VERSION ""
NS_ :

BS_:
BU_: DBG BLE GPS MOTOR SENSOR MASTER

BO_ 90 MASTER_HEARTBEAT: 1 MASTER
 SG_ MASTER_HEARTBEAT_cmd : 0|8@1+ (1,0) [0|0] "" MOTOR, SENSOR, GPS

BO_ 91 MOTOR_HEARTBEAT: 1 MOTOR
 SG_ MOTOR_HEARTBEAT_cmd : 0|8@1+ (1,0) [0|0] "" MASTER

BO_ 92 SENSOR_HEARTBEAT: 1 SENSOR
 SG_ SENSOR_HEARTBEAT_cmd : 0|8@1+ (1,0) [0|0] "" MASTER

BO_ 93 GPS_HEARTBEAT: 1 GPS
 SG_ GPS_HEARTBEAT_cmd : 0|8@1+ (1,0) [0|0] "" MASTER, BLE

BO_ 94 BLE_HEARTBEAT: 1 BLE
 SG_ BLE_HEARTBEAT_cmd : 0|8@1+ (1,0) [0|0] "" MASTER, GPS

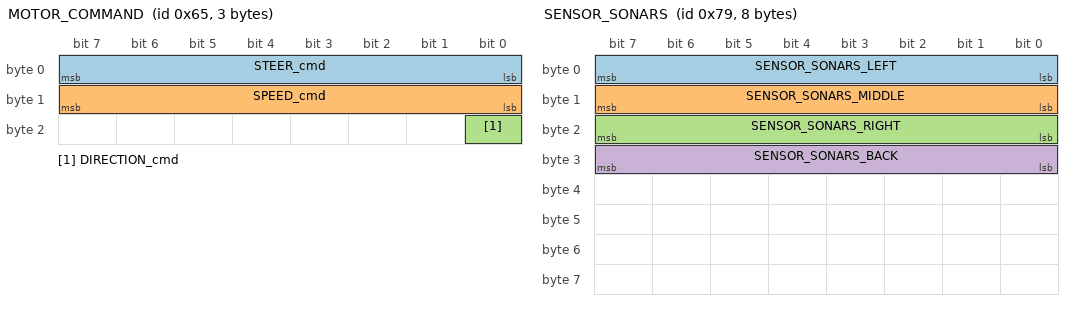
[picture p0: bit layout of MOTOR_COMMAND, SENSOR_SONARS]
BO_ 101 MOTOR_COMMAND: 3 MASTER
 SG_ STEER_cmd : 0|8@1- (1,0) [-2|2] "" MOTOR
 SG_ SPEED_cmd : 8|8@1- (0.1,0) [0|3.0] "m/s" MOTOR
 SG_ DIRECTION_cmd : 16|1@1+ (1,0) [0|0] "" MOTOR

BO_ 121 SENSOR_SONARS: 8 SENSOR
 SG_ SENSOR_SONARS_LEFT : 0|8@1+ (1,0) [0|0] "" MASTER
 SG_ SENSOR_SONARS_MIDDLE : 8|8@1+ (1,0) [0|0] "" MASTER
 SG_ SENSOR_SONARS_RIGHT : 16|8@1+ (1,0) [0|0] "" MASTER
 SG_ SENSOR_SONARS_BACK : 24|8@1+ (1,0) [0|0] "" MASTER

BO_ 141 DIRECTION_GPS: 2 GPS
 SG_ DIRECTION_VAL : 0|8@1- (1,0) [-2|2] "" MASTER
 SG_ DESTINATION_REACHED : 8|1@1+ (1,0) [0|0] "" MASTER

BO_ 161 SPEED_MOTOR: 2 MOTOR
 SG_ MOTOR_SPEED : 0|12@1+ (0.001,0) [0|0] "mph" MASTER

BO_ 181 APP_DATA: 8 BLE
 SG_ START_CAR : 0|2@1+ (1,0) [0|0] "" MASTER, DBG

BO_ 182 APP_DATA_LAT_LONG: 8 BLE
 SG_ DEST_LAT : 0|26@1+ (1,0) [0|0] "" MASTER,GPS
 SG_ DEST_LONG : 26|27@1+ (1,0) [0|0] "" MASTER,GPS

BO_ 191 HEADING: 4 GPS
 SG_ HEADING_VAL : 0|32@1+ (0.000001,0) [0|0] "" MOTOR, DBG

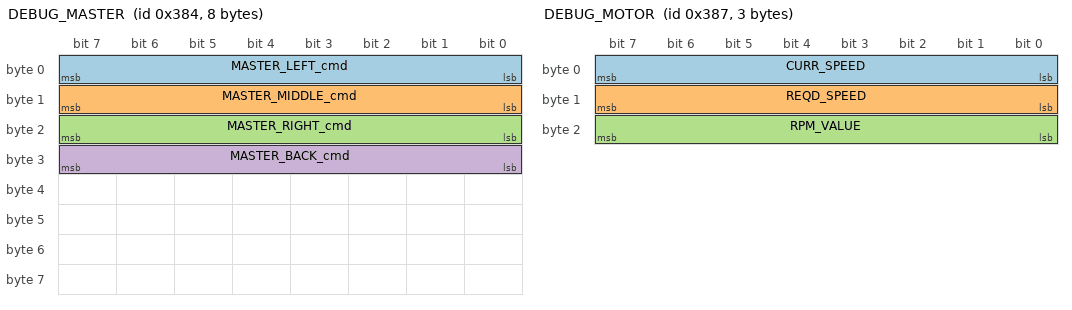
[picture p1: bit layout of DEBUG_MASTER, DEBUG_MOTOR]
BO_ 900 DEBUG_MASTER: 8 MASTER
 SG_ MASTER_LEFT_cmd : 0|8@1+ (1,0) [0|0] "" DBG
 SG_ MASTER_MIDDLE_cmd : 8|8@1+ (1,0) [0|0] "" DBG
 SG_ MASTER_RIGHT_cmd : 16|8@1+ (1,0) [0|0] "" DBG
 SG_ MASTER_BACK_cmd : 24|8@1+ (1,0) [0|0] "" DBG

BO_ 901 DEBUG_GPS: 8 GPS
 SG_ CURR_LAT : 0|32@1+ (0.000001,0) [36.000000|38.000000] "" DBG
 SG_ CURR_LONG : 32|32@1+ (0.000001,-123) [-123.000000|-120.000000] "" DBG

BO_ 902 DEBUG_COMPASS: 2 GPS
 SG_ HEADING : 0|16@1+ (1,0) [0|360] "degrees" DBG

BO_ 903 DEBUG_MOTOR: 3 MOTOR
 SG_ CURR_SPEED : 0|8@1+ (0.01,0) [0|0] "m/s" DBG
 SG_ REQD_SPEED : 8|8@1+ (0.01,0) [0|0] "m/s" DBG
 SG_ RPM_VALUE : 16|8@1+ (1,0) [0|0] "" DBG

BO_ 904 DEBUG_NAVIGATION: 8 GPS
 SG_ DIST_DIFF : 0|32@1+ (0.000001,0) [0|0] "m" DBG
 SG_ HEAD_DIFF : 32|32@1+ (0.000001,0) [0|0] "Degrees" DBG

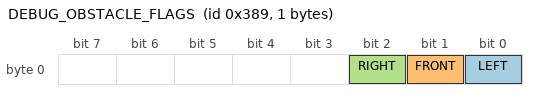
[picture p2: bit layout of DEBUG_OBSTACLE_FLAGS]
BO_ 905 DEBUG_OBSTACLE_FLAGS: 1 MASTER
 SG_ LEFT : 0|1@1+ (1,0) [0|0] "" DBG
 SG_ FRONT : 1|1@1+ (1,0) [0|0] "" DBG
 SG_ RIGHT : 2|1@1+ (1,0) [0|0] "" DBG

BO_ 899 DEBUG_BEARING: 4 GPS
 SG_ BEARING : 0|32@1+ (0.000001,0) [0|0] "degrees" DBG,MOTOR

BO_ 897 NXT_COORD: 8 GPS
 SG_ LAT : 0|32@1+ (0.000001,0) [36.000000|38.000000] "" DBG
 SG_ LONG : 32|32@1+ (0.000001,-123) [-123.000000|-120.000000] "" DBG

BO_ 896 CHECKPOINTS: 1 GPS
 SG_ COUNT : 0|8@1+ (1,0) [0|0] "" MOTOR

BO_ 898 DEBUG_CHECKPOINT: 1 GPS
 SG_ INDEX : 0|8@1+ (1,0) [0|0] "" DBG, MOTOR

CM_ BU_ DRIVER "The driver controller driving the car";
CM_ BU_ MOTOR "The motor controller of the car";
CM_ BU_ SENSOR "The sensor controller of the car";
CM_ BU_ BLE "The bluetooth controller of car";
CM_ BU_ GPS "The GPS controller of the car";
CM_ BO_ 100 "Sync message used to synchronize the controllers";

BA_DEF_ "BusType" STRING ;
BA_DEF_ BO_ "GenMsgCycleTime" INT 0 0;
BA_DEF_ SG_ "FieldType" STRING ;

BA_DEF_DEF_ "BusType" "CAN";
BA_DEF_DEF_ "FieldType" "";
BA_DEF_DEF_ "GenMsgCycleTime" 0;

BA_ "GenMsgCycleTime" BO_ 500 100;
BA_ "GenMsgCycleTime" BO_ 100 1000;
BA_ "GenMsgCycleTime" BO_ 101 100;
BA_ "GenMsgCycleTime" BO_ 400 100;
BA_ "GenMsgCycleTime" BO_ 200 100;
BA_ "FieldType" SG_ 500 DBC_TEST1_enum "DBC_TEST1_enum";
BA_ "FieldType" SG_ 100 DRIVER_HEARTBEAT_cmd "DRIVER_HEARTBEAT_cmd";
VAL_ 500 DBC_TEST1_enum 2 "DBC_TEST1_enum_val_two" 1 "DBC_TEST1_enum_val_one" ;
VAL_ 100 DRIVER_HEARTBEAT_cmd 2 "DRIVER_HEARTBEAT_cmd_REBOOT" 1 "DRIVER_HEARTBEAT_cmd_SYNC" 0 "DRIVER_HEARTBEAT_cmd_NOOP" ;
